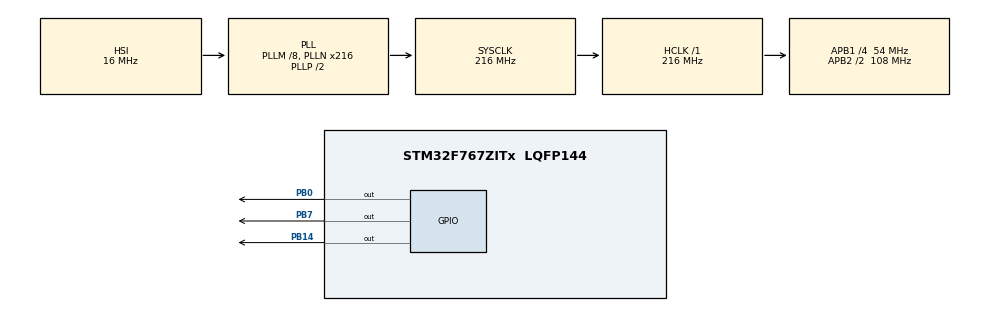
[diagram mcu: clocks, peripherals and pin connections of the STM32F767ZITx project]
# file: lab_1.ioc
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Mcu.Family=STM32F7
Mcu.Name=STM32F767ZITx
Mcu.Package=LQFP144
NVIC.PriorityGroup=NVIC_PRIORITYGROUP_4
PB0.Signal=GPIO_Output
PB14.Signal=GPIO_Output
PB7.Signal=GPIO_Output
ProjectManager.HeapSize=0x200
ProjectManager.StackSize=0x400
ProjectManager.TargetToolchain=STM32CubeIDE
RCC.AHBFreq_Value=216000000
RCC.APB1CLKDivider=RCC_HCLK_DIV4
RCC.APB1Freq_Value=54000000
RCC.APB1TimFreq_Value=108000000
RCC.APB2CLKDivider=RCC_HCLK_DIV2
RCC.APB2Freq_Value=108000000
RCC.APB2TimFreq_Value=216000000
RCC.CortexFreq_Value=216000000
RCC.HCLKFreq_Value=216000000
RCC.HSE_VALUE=25000000
RCC.HSI_VALUE=16000000
RCC.LSE_VALUE=32768
RCC.PLLM=8
RCC.PLLN=216
RCC.SYSCLKFreq_VALUE=216000000
RCC.SYSCLKSource=RCC_SYSCLKSOURCE_PLLCLK
RCC.USBFreq_Value=216000000
RCC.VCOOutputFreq_Value=432000000
board=custom

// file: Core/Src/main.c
/* USER CODE BEGIN Header */
/**
  ******************************************************************************
  * @file           : main.c
  * @brief          : Main program body
  ******************************************************************************
  * @attention
  *
  * <h2><center>&copy; Copyright (c) 2020 STMicroelectronics.
  * All rights reserved.</center></h2>
  *
  * This software component is licensed by ST under BSD 3-Clause license,
  * the "License"; You may not use this file except in compliance with the
  * License. You may obtain a copy of the License at:
  *                        opensource.org/licenses/BSD-3-Clause
  *
  ******************************************************************************
  */
/* USER CODE END Header */

#include "main.h"

/* USER CODE BEGIN PV */
uint8_t num=0;
uint8_t n0=0;
uint8_t n1=0;
uint8_t n2=0;
/* USER CODE END PV */

void SystemClock_Config(void);
static void MX_GPIO_Init(void);
/* USER CODE BEGIN PFP */
void delay(uint32_t ms);
void displayNum(uint8_t num);
void simulate_GPIO(uint8_t num);
/* USER CODE END PFP */

int main(void)
{

  /* MCU Configuration--------------------------------------------------------*/

  /* Reset of all peripherals, Initializes the Flash interface and the Systick. */
  HAL_Init();

  /* Configure the system clock */
  SystemClock_Config();

  /* Initialize all configured peripherals */
  MX_GPIO_Init();

  /* Infinite loop */
  /* USER CODE BEGIN WHILE */
  while (1)
  {
	  if(num<=7){
		  num++;
	  }else{
		  num=0;
	  }

	  HAL_GPIO_TogglePin(GPIOB, GPIO_PIN_0);
	  delay(300);
    /* USER CODE END WHILE */

  }
}

void SystemClock_Config(void)
{
  RCC_OscInitTypeDef RCC_OscInitStruct = {0};
  RCC_ClkInitTypeDef RCC_ClkInitStruct = {0};

  /** Configure the main internal regulator output voltage
  */
  __HAL_RCC_PWR_CLK_ENABLE();
  __HAL_PWR_VOLTAGESCALING_CONFIG(PWR_REGULATOR_VOLTAGE_SCALE1);
  /** Initializes the CPU, AHB and APB busses clocks
  */
  RCC_OscInitStruct.OscillatorType = RCC_OSCILLATORTYPE_HSI;
  RCC_OscInitStruct.HSIState = RCC_HSI_ON;
  RCC_OscInitStruct.HSICalibrationValue = RCC_HSICALIBRATION_DEFAULT;
  RCC_OscInitStruct.PLL.PLLState = RCC_PLL_ON;
  RCC_OscInitStruct.PLL.PLLSource = RCC_PLLSOURCE_HSI;
  RCC_OscInitStruct.PLL.PLLM = 8;
  RCC_OscInitStruct.PLL.PLLN = 216;
  RCC_OscInitStruct.PLL.PLLP = RCC_PLLP_DIV2;
  RCC_OscInitStruct.PLL.PLLQ = 2;
  if (HAL_RCC_OscConfig(&RCC_OscInitStruct) != HAL_OK)
  {
    Error_Handler();
  }
  /** Activate the Over-Drive mode
  */
  if (HAL_PWREx_EnableOverDrive() != HAL_OK)
  {
    Error_Handler();
  }
  /** Initializes the CPU, AHB and APB busses clocks
  */
  RCC_ClkInitStruct.ClockType = RCC_CLOCKTYPE_HCLK|RCC_CLOCKTYPE_SYSCLK
                              |RCC_CLOCKTYPE_PCLK1|RCC_CLOCKTYPE_PCLK2;
  RCC_ClkInitStruct.SYSCLKSource = RCC_SYSCLKSOURCE_PLLCLK;
  RCC_ClkInitStruct.AHBCLKDivider = RCC_SYSCLK_DIV1;
  RCC_ClkInitStruct.APB1CLKDivider = RCC_HCLK_DIV4;
  RCC_ClkInitStruct.APB2CLKDivider = RCC_HCLK_DIV2;

  if (HAL_RCC_ClockConfig(&RCC_ClkInitStruct, FLASH_LATENCY_7) != HAL_OK)
  {
    Error_Handler();
  }
}

static void MX_GPIO_Init(void)
{
  GPIO_InitTypeDef GPIO_InitStruct = {0};

  /* GPIO Ports Clock Enable */
  __HAL_RCC_GPIOB_CLK_ENABLE();

  /*Configure GPIO pin Output Level */
  HAL_GPIO_WritePin(GPIOB, GPIO_PIN_0|GPIO_PIN_14|GPIO_PIN_7, GPIO_PIN_RESET);

  /*Configure GPIO pins : PB0 PB14 PB7 */
  GPIO_InitStruct.Pin = GPIO_PIN_0|GPIO_PIN_14|GPIO_PIN_7;
  GPIO_InitStruct.Mode = GPIO_MODE_OUTPUT_PP;
  GPIO_InitStruct.Pull = GPIO_NOPULL;
  GPIO_InitStruct.Speed = GPIO_SPEED_FREQ_LOW;
  HAL_GPIO_Init(GPIOB, &GPIO_InitStruct);

}

/* USER CODE BEGIN 4 */
void delay(uint32_t ms){
	volatile uint32_t i,j;

	for(i=0;i<ms;i++){
		for(j=0;j<32000;j++){

		}
	}

	return;
}

void displayNum(uint8_t num) {
			simulate_GPIO(num);

			switch(num){
			case 0:
				HAL_GPIO_WritePin(GPIOB, GPIO_PIN_14, GPIO_PIN_RESET);
				HAL_GPIO_WritePin(GPIOB, GPIO_PIN_7, GPIO_PIN_RESET);
				HAL_GPIO_WritePin(GPIOB, GPIO_PIN_0, GPIO_PIN_RESET);
				break;
			case 1:
				HAL_GPIO_WritePin(GPIOB, GPIO_PIN_14, GPIO_PIN_RESET);
				HAL_GPIO_WritePin(GPIOB, GPIO_PIN_7, GPIO_PIN_RESET);
				HAL_GPIO_WritePin(GPIOB, GPIO_PIN_0, GPIO_PIN_SET);
				break;
			case 2:
				HAL_GPIO_WritePin(GPIOB, GPIO_PIN_14, GPIO_PIN_RESET);
				HAL_GPIO_WritePin(GPIOB, GPIO_PIN_7, GPIO_PIN_SET);
				HAL_GPIO_WritePin(GPIOB, GPIO_PIN_0, GPIO_PIN_RESET);
				break;
			case 3:
				HAL_GPIO_WritePin(GPIOB, GPIO_PIN_14, GPIO_PIN_RESET);
				HAL_GPIO_WritePin(GPIOB, GPIO_PIN_7, GPIO_PIN_SET);
				HAL_GPIO_WritePin(GPIOB, GPIO_PIN_0, GPIO_PIN_SET);
				break;
			case 4:
				HAL_GPIO_WritePin(GPIOB, GPIO_PIN_14, GPIO_PIN_SET);
				HAL_GPIO_WritePin(GPIOB, GPIO_PIN_7, GPIO_PIN_RESET);
				HAL_GPIO_WritePin(GPIOB, GPIO_PIN_0, GPIO_PIN_RESET);
				break;
			case 5:
				HAL_GPIO_WritePin(GPIOB, GPIO_PIN_14, GPIO_PIN_SET);
				HAL_GPIO_WritePin(GPIOB, GPIO_PIN_7, GPIO_PIN_RESET);
				HAL_GPIO_WritePin(GPIOB, GPIO_PIN_0, GPIO_PIN_SET);
				break;
			case 6:
				HAL_GPIO_WritePin(GPIOB, GPIO_PIN_14, GPIO_PIN_SET);
				HAL_GPIO_WritePin(GPIOB, GPIO_PIN_7, GPIO_PIN_SET);
				HAL_GPIO_WritePin(GPIOB, GPIO_PIN_0, GPIO_PIN_RESET);
				break;
			case 7:
				HAL_GPIO_WritePin(GPIOB, GPIO_PIN_14, GPIO_PIN_SET);
				HAL_GPIO_WritePin(GPIOB, GPIO_PIN_7, GPIO_PIN_SET);
				HAL_GPIO_WritePin(GPIOB, GPIO_PIN_0, GPIO_PIN_SET);
				break;
			default:
				HAL_GPIO_WritePin(GPIOB, GPIO_PIN_14, GPIO_PIN_RESET);
				HAL_GPIO_WritePin(GPIOB, GPIO_PIN_7, GPIO_PIN_RESET);
				HAL_GPIO_WritePin(GPIOB, GPIO_PIN_0, GPIO_PIN_RESET);
			}

}

void simulate_GPIO(uint8_t num){

	switch(num){
	case 0:
		n0=0;
		n1=0;
		n2=0;
		break;
	case 1:
		n0=1;
		n1=0;
		n2=0;
		break;
	case 2:
		n0=0;
		n1=1;
		n2=0;
		break;
	case 3:
		n0=1;
		n1=1;
		n2=0;
		break;
	case 4:
		n0=0;
		n1=0;
		n2=1;
		break;
	case 5:
		n0=1;
		n1=0;
		n2=1;
		break;
	case 6:
		n0=0;
		n1=1;
		n2=1;
		break;
	case 7:
		n0=1;
		n1=1;
		n2=1;
		break;
	default:
		n0=0;
		n1=0;
		n2=0;
	}

}
/* USER CODE END 4 */

void Error_Handler(void)
{
}

/************************ (C) COPYRIGHT STMicroelectronics *****END OF FILE****/
